AUTOSAR XML (schema 4.0)
package /Battery_EV_Components
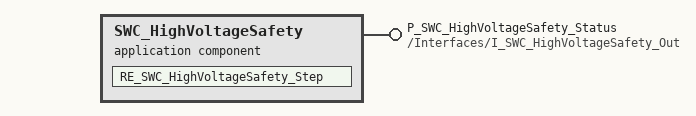
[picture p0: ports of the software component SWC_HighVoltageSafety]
  application sw component type SWC_HighVoltageSafety  # AUTOSAR Application SWC SWC_HighVoltageSafety for Battery EV Safety
    provide port P_SWC_HighVoltageSafety_Status: provided-interface=/Interfaces/I_SWC_HighVoltageSafety_Out
    behavior SWC_HighVoltageSafety_Behavior
      runnable RE_SWC_HighVoltageSafety_Step: symbol=SWC_HighVoltageSafety_Step
  sender receiver interface I_SWC_HighVoltageSafety_Out
    data DE_SWC_HighVoltageSafety_Health: type=/AUTOSAR/Platform/uint32
